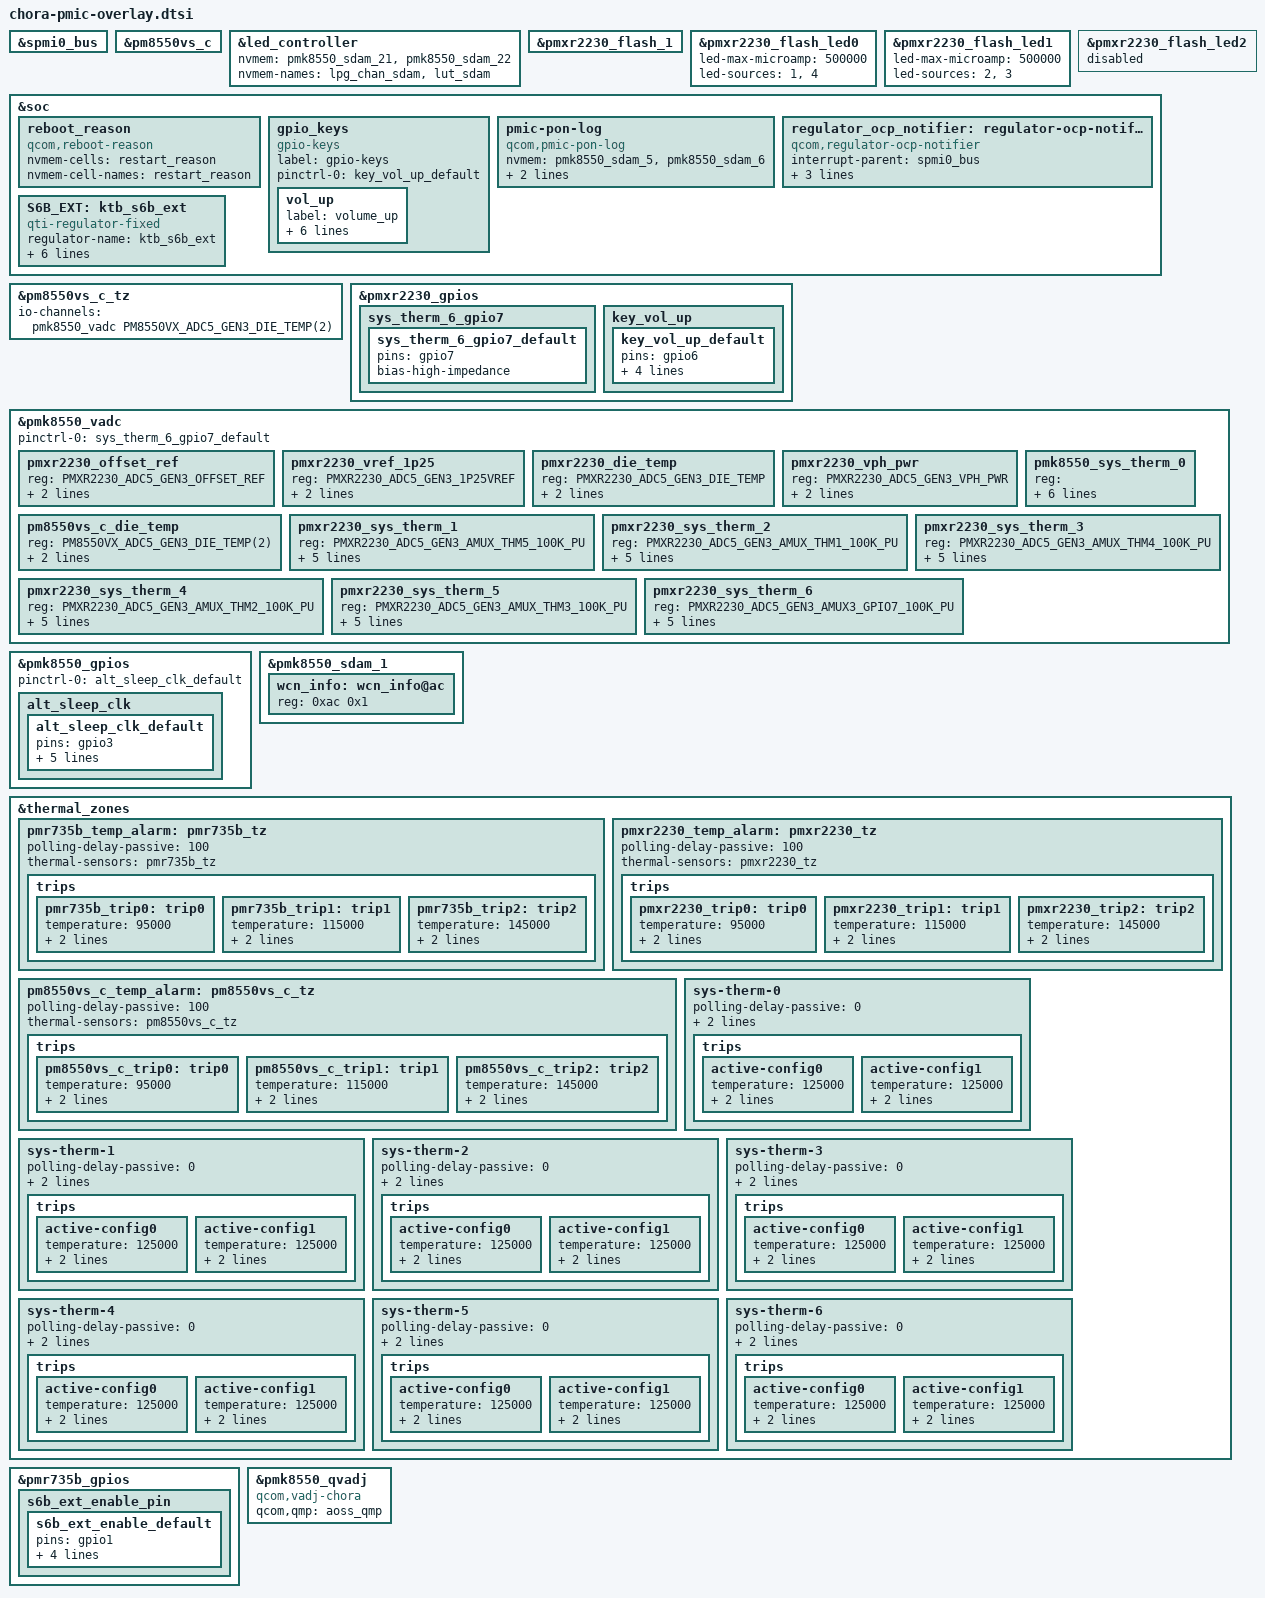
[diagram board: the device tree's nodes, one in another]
// SPDX-License-Identifier: BSD-3-Clause
/*
 * Copyright (c) Qualcomm Technologies, Inc. and/or its subsidiaries.
 */

#include <dt-bindings/gpio/gpio.h>
#include <dt-bindings/iio/qcom,spmi-adc5-gen3-pmxr2230.h>
#include <dt-bindings/iio/qcom,spmi-adc5-gen3-pm8550vx.h>
#include <dt-bindings/pinctrl/qcom,pmic-gpio.h>

&spmi0_bus {
	#include "pmk8550.dtsi"
	#include "pmxr2230.dtsi"
	#include "pm8550vs.dtsi"
	#include "pmr735b.dtsi"
};

&pm8550vs_c {
	status = "ok";
};

&led_controller {
	nvmem = <&pmk8550_sdam_21>, <&pmk8550_sdam_22>;
	nvmem-names = "lpg_chan_sdam", "lut_sdam";
	status = "ok";
};

&pmxr2230_flash_1 {
	status = "ok";
};

&pmxr2230_flash_led0 {
	led-max-microamp = <500000>;
	led-sources = <1>, <4>;
};

&pmxr2230_flash_led1 {
	led-max-microamp = <500000>;
	led-sources = <2>, <3>;
};

&pmxr2230_flash_led2 {
	status = "disabled";
};

&soc {
	reboot_reason {
		compatible = "qcom,reboot-reason";
		nvmem-cells = <&restart_reason>;
		nvmem-cell-names = "restart_reason";
	};
};

&pm8550vs_c_tz {
	io-channels = <&pmk8550_vadc PM8550VX_ADC5_GEN3_DIE_TEMP(2)>;
	io-channel-names = "thermal";
};

&pmxr2230_gpios {
	sys_therm_6_gpio7 {
		sys_therm_6_gpio7_default: sys_therm_6_gpio7_default {
			pins = "gpio7";
			bias-high-impedance;
		};
	};
};

&pmk8550_vadc {
	pinctrl-names = "default";
	pinctrl-0 = <&sys_therm_6_gpio7_default>;

	/* PMXR2230 Channel nodes */
	pmxr2230_offset_ref {
		reg = <PMXR2230_ADC5_GEN3_OFFSET_REF>;
		label = "pmxr2230_offset_ref";
		qcom,pre-scaling = <1 1>;
	};

	pmxr2230_vref_1p25 {
		reg = <PMXR2230_ADC5_GEN3_1P25VREF>;
		label = "pmxr2230_vref_1p25";
		qcom,pre-scaling = <1 1>;
	};

	pmxr2230_die_temp {
		reg = <PMXR2230_ADC5_GEN3_DIE_TEMP>;
		label = "pmxr2230_die_temp";
		qcom,pre-scaling = <1 1>;
	};

	pmxr2230_vph_pwr {
		reg = <PMXR2230_ADC5_GEN3_VPH_PWR>;
		label = "pmxr2230_vph_pwr";
		qcom,pre-scaling = <1 3>;
	};

	pm8550vs_c_die_temp {
		reg = <PM8550VX_ADC5_GEN3_DIE_TEMP(2)>;
		label = "pm8550vs_c_die_temp";
		qcom,pre-scaling = <1 1>;
	};

	pmk8550_sys_therm_0 {
		reg = <PMK8550_ADC5_GEN3_AMUX_THM1_XO_THERM_100K_PU>;
		label = "pmk8550_sys_therm_0";
		qcom,ratiometric;
		qcom,hw-settle-time = <200>;
		qcom,pre-scaling = <1 1>;
		qcom,adc-tm-type = <1>;
	};

	pmxr2230_sys_therm_1 {
		reg = <PMXR2230_ADC5_GEN3_AMUX_THM5_100K_PU>;
		label = "pmxr2230_sys_therm_1";
		qcom,ratiometric;
		qcom,hw-settle-time = <200>;
		qcom,pre-scaling = <1 1>;
		qcom,adc-tm-type = <1>;
	};

	pmxr2230_sys_therm_2 {
		reg = <PMXR2230_ADC5_GEN3_AMUX_THM1_100K_PU>;
		label = "pmxr2230_sys_therm_2";
		qcom,ratiometric;
		qcom,hw-settle-time = <200>;
		qcom,pre-scaling = <1 1>;
		qcom,adc-tm-type = <1>;
	};

	pmxr2230_sys_therm_3 {
		reg = <PMXR2230_ADC5_GEN3_AMUX_THM4_100K_PU>;
		label = "pmxr2230_sys_therm_3";
		qcom,ratiometric;
		qcom,hw-settle-time = <200>;
		qcom,pre-scaling = <1 1>;
		qcom,adc-tm-type = <1>;
	};

	pmxr2230_sys_therm_4 {
		reg = <PMXR2230_ADC5_GEN3_AMUX_THM2_100K_PU>;
		label = "pmxr2230_sys_therm_4";
		qcom,ratiometric;
		qcom,hw-settle-time = <200>;
		qcom,pre-scaling = <1 1>;
		qcom,adc-tm-type = <1>;
	};

	pmxr2230_sys_therm_5 {
		reg = <PMXR2230_ADC5_GEN3_AMUX_THM3_100K_PU>;
		label = "pmxr2230_sys_therm_5";
		qcom,ratiometric;
		qcom,hw-settle-time = <200>;
		qcom,pre-scaling = <1 1>;
		qcom,adc-tm-type = <1>;
	};

	pmxr2230_sys_therm_6 {
		reg = <PMXR2230_ADC5_GEN3_AMUX3_GPIO7_100K_PU>;
		label = "pmxr2230_sys_therm_6";
		qcom,ratiometric;
		qcom,hw-settle-time = <200>;
		qcom,pre-scaling = <1 1>;
		qcom,adc-tm-type = <1>;
	};
};

&pmxr2230_gpios {
	key_vol_up {
		key_vol_up_default: key_vol_up_default {
			pins = "gpio6";
			function = "normal";
			input-enable;
			bias-pull-up;
			power-source = <1>;
		};
	};
};

&soc {
	gpio_keys {
		compatible = "gpio-keys";
		label = "gpio-keys";
		pinctrl-names = "default";
		pinctrl-0 = <&key_vol_up_default>;
		vol_up {
			label = "volume_up";
			gpios = <&pmxr2230_gpios 6 GPIO_ACTIVE_LOW>;
			linux,input-type = <1>;
			linux,code = <KEY_VOLUMEUP>;
			gpio-key,wakeup;
			debounce-interval = <15>;
			linux,can-disable;
		};
	};

	pmic-pon-log {
		compatible = "qcom,pmic-pon-log";
		nvmem = <&pmk8550_sdam_5>, <&pmk8550_sdam_6>;
		nvmem-names = "pon_log0", "pon_log1";
		depends-on-supply = <&wdog>;
	};

	regulator_ocp_notifier: regulator-ocp-notifier {
		compatible = "qcom,regulator-ocp-notifier";
		interrupt-parent = <&spmi0_bus>;
		interrupts = <0x0 0x71 0x1 IRQ_TYPE_EDGE_RISING>;
		nvmem-cells = <&ocp_log>;
		nvmem-cell-names = "ocp_log";
	};
};

&pmk8550_gpios {
	pinctrl-0 = <&alt_sleep_clk_default>;
	pinctrl-names = "default";

	alt_sleep_clk {
		alt_sleep_clk_default: alt_sleep_clk_default {
			pins = "gpio3";
			function = "func1";
			input-disable;
			output-enable;
			bias-disable;
			power-source = <0>;
		};
	};
};

&pmk8550_sdam_1 {
	wcn_info: wcn_info@ac {
		reg = <0xac 0x1>;
	};
};

&thermal_zones {
	pmr735b_temp_alarm: pmr735b_tz {
		polling-delay-passive = <100>;
		thermal-sensors = <&pmr735b_tz>;

		trips {
			pmr735b_trip0: trip0 {
				temperature = <95000>;
				hysteresis = <0>;
				type = "passive";
			};

			pmr735b_trip1: trip1 {
				temperature = <115000>;
				hysteresis = <0>;
				type = "hot";
			};

			pmr735b_trip2: trip2 {
				temperature = <145000>;
				hysteresis = <0>;
				type = "critical";
			};
		};
	};

	pmxr2230_temp_alarm: pmxr2230_tz {
		polling-delay-passive = <100>;
		thermal-sensors = <&pmxr2230_tz>;

		trips {
			pmxr2230_trip0: trip0 {
				temperature = <95000>;
				hysteresis = <0>;
				type = "passive";
			};

			pmxr2230_trip1: trip1 {
				temperature = <115000>;
				hysteresis = <0>;
				type = "hot";
			};

			pmxr2230_trip2: trip2 {
				temperature = <145000>;
				hysteresis = <0>;
				type = "critical";
			};
		};
	};

	pm8550vs_c_temp_alarm: pm8550vs_c_tz {
		polling-delay-passive = <100>;
		thermal-sensors = <&pm8550vs_c_tz>;

		trips {
			pm8550vs_c_trip0: trip0 {
				temperature = <95000>;
				hysteresis = <0>;
				type = "passive";
			};

			pm8550vs_c_trip1: trip1 {
				temperature = <115000>;
				hysteresis = <0>;
				type = "hot";
			};

			pm8550vs_c_trip2: trip2 {
				temperature = <145000>;
				hysteresis = <0>;
				type = "critical";
			};
		};
	};

	/* XO_THERM */
	sys-therm-0 {
		polling-delay-passive = <0>;
		thermal-sensors = <&pmk8550_vadc PMK8550_ADC5_GEN3_AMUX_THM1_XO_THERM_100K_PU>;

		trips {
			active-config0 {
				temperature = <125000>;
				hysteresis = <1000>;
				type = "passive";
			};

			active-config1 {
				temperature = <125000>;
				hysteresis = <1000>;
				type = "passive";
			};
		};
	};

	/* GNSS_THERM */
	sys-therm-1 {
		polling-delay-passive = <0>;
		thermal-sensors = <&pmk8550_vadc PMXR2230_ADC5_GEN3_AMUX_THM5_100K_PU>;

		trips {
			active-config0 {
				temperature = <125000>;
				hysteresis = <1000>;
				type = "passive";
			};

			active-config1 {
				temperature = <125000>;
				hysteresis = <1000>;
				type = "passive";
			};
		};
	};

	/* PA_THERM1 */
	sys-therm-2 {
		polling-delay-passive = <0>;
		thermal-sensors = <&pmk8550_vadc PMXR2230_ADC5_GEN3_AMUX_THM1_100K_PU>;

		trips {
			active-config0 {
				temperature = <125000>;
				hysteresis = <1000>;
				type = "passive";
			};

			active-config1 {
				temperature = <125000>;
				hysteresis = <1000>;
				type = "passive";
			};
		};
	};

	/* QUIET_THERM */
	sys-therm-3 {
		polling-delay-passive = <0>;
		thermal-sensors = <&pmk8550_vadc PMXR2230_ADC5_GEN3_AMUX_THM4_100K_PU>;

		trips {
			active-config0 {
				temperature = <125000>;
				hysteresis = <1000>;
				type = "passive";
			};

			active-config1 {
				temperature = <125000>;
				hysteresis = <1000>;
				type = "passive";
			};
		};
	};

	/* UFS_THERM */
	sys-therm-4 {
		polling-delay-passive = <0>;
		thermal-sensors = <&pmk8550_vadc PMXR2230_ADC5_GEN3_AMUX_THM2_100K_PU>;

		trips {
			active-config0 {
				temperature = <125000>;
				hysteresis = <1000>;
				type = "passive";
			};

			active-config1 {
				temperature = <125000>;
				hysteresis = <1000>;
				type = "passive";
			};
		};
	};

	/* PA_THERM2 */
	sys-therm-5 {
		polling-delay-passive = <0>;
		thermal-sensors = <&pmk8550_vadc PMXR2230_ADC5_GEN3_AMUX_THM3_100K_PU>;

		trips {
			active-config0 {
				temperature = <125000>;
				hysteresis = <1000>;
				type = "passive";
			};

			active-config1 {
				temperature = <125000>;
				hysteresis = <1000>;
				type = "passive";
			};
		};
	};

	/* CAM_THERM */
	sys-therm-6 {
		polling-delay-passive = <0>;
		thermal-sensors = <&pmk8550_vadc PMXR2230_ADC5_GEN3_AMUX3_GPIO7_100K_PU>;

		trips {
			active-config0 {
				temperature = <125000>;
				hysteresis = <1000>;
				type = "passive";
			};

			active-config1 {
				temperature = <125000>;
				hysteresis = <1000>;
				type = "passive";
			};
		};
	};
};

&pmr735b_gpios {
	s6b_ext_enable_pin {
		s6b_ext_enable_default: s6b_ext_enable_default {
			pins = "gpio1";
			function = "normal";
			bias-disable;
			output-low;
			power-source = <0>;
		};
	};
};

&soc {
	S6B_EXT: ktb_s6b_ext {
		compatible = "qti-regulator-fixed";
		regulator-name = "ktb_s6b_ext";
		regulator-min-microvolt	= <2200000>;
		regulator-max-microvolt	= <2200000>;
		startup-delay-us = <1000>;
		enable-active-high;
		gpio = <&pmr735b_gpios 1 0>;
		pinctrl-names =	"default";
		pinctrl-0 = <&s6b_ext_enable_default>;
	};
};

&pmk8550_qvadj {
	compatible = "qcom,vadj-chora", "qcom,vadj";
	qcom,qmp = <&aoss_qmp>;
};
